# iom480ae register map
Registers are 32-bit, access not given, no defined reset value unless marked. A register's access mark holds for its fields unless they carry their own. Addresses are absolute; registers are grouped by the start of their names; [hi:lo] are bit positions; 'fields as' and 'values as' point back to an identical list.

## TMR01
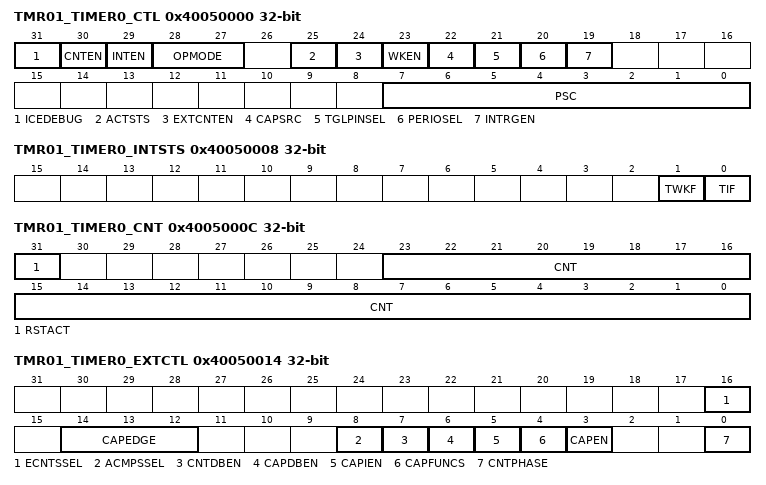
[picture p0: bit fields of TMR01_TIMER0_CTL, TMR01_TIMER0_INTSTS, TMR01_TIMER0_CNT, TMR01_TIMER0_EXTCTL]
0x40050000 TMR01_TIMER0_CTL
  [31] ICEDEBUG, [30] CNTEN, [29] INTEN, [28:27] OPMODE, [25] ACTSTS, [24] EXTCNTEN, [23] WKEN, [22] CAPSRC, [21] TGLPINSEL, [20] PERIOSEL, [19] INTRGEN, [7:0] PSC
0x40050004 TMR01_TIMER0_CMP
  [23:0] CMPDAT
0x40050008 TMR01_TIMER0_INTSTS
  [1] TWKF, [0] TIF
0x4005000C TMR01_TIMER0_CNT
  [31] RSTACT, [23:0] CNT
0x40050010 TMR01_TIMER0_CAP
  [23:0] CAPDAT
0x40050014 TMR01_TIMER0_EXTCTL
  [16] ECNTSSEL, [14:12] CAPEDGE, [8] ACMPSSEL, [7] CNTDBEN, [6] CAPDBEN, [5] CAPIEN, [4] CAPFUNCS, [3] CAPEN, [0] CNTPHASE
0x40050018 TMR01_TIMER0_EINTSTS
  [0] CAPIF
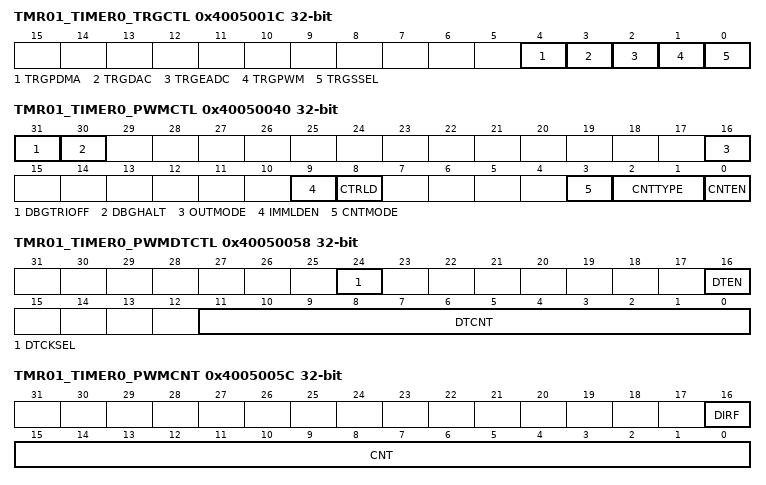
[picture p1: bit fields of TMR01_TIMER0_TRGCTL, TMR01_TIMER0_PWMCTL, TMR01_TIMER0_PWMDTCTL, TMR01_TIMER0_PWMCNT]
0x4005001C TMR01_TIMER0_TRGCTL
  [4] TRGPDMA, [3] TRGDAC, [2] TRGEADC, [1] TRGPWM, [0] TRGSSEL
0x40050020 TMR01_TIMER0_ALTCTL
  [0] FUNCSEL
0x40050040 TMR01_TIMER0_PWMCTL
  [31] DBGTRIOFF, [30] DBGHALT, [16] OUTMODE, [9] IMMLDEN, [8] CTRLD, [3] CNTMODE, [2:1] CNTTYPE, [0] CNTEN
0x40050044 TMR01_TIMER0_PWMCLKSRC
  [2:0] CLKSRC
0x40050048 TMR01_TIMER0_PWMCLKPSC
  [11:0] CLKPSC
0x4005004C TMR01_TIMER0_PWMCNTCLR
  [0] CNTCLR
0x40050050 TMR01_TIMER0_PWMPERIOD
  [15:0] PERIOD
0x40050054 TMR01_TIMER0_PWMCMPDAT
  [15:0] CMP
0x40050058 TMR01_TIMER0_PWMDTCTL
  [24] DTCKSEL, [16] DTEN, [11:0] DTCNT
0x4005005C TMR01_TIMER0_PWMCNT
  [16] DIRF, [15:0] CNT
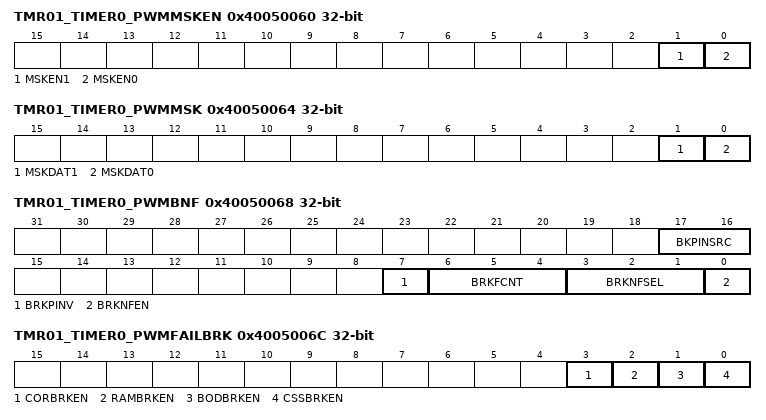
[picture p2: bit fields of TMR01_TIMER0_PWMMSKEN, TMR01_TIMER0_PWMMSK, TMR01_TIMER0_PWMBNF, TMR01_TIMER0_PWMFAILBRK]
0x40050060 TMR01_TIMER0_PWMMSKEN
  [1] MSKEN1, [0] MSKEN0
0x40050064 TMR01_TIMER0_PWMMSK
  [1] MSKDAT1, [0] MSKDAT0
0x40050068 TMR01_TIMER0_PWMBNF
  [17:16] BKPINSRC, [7] BRKPINV, [6:4] BRKFCNT, [3:1] BRKNFSEL, [0] BRKNFEN
0x4005006C TMR01_TIMER0_PWMFAILBRK
  [3] CORBRKEN, [2] RAMBRKEN, [1] BODBRKEN, [0] CSSBRKEN
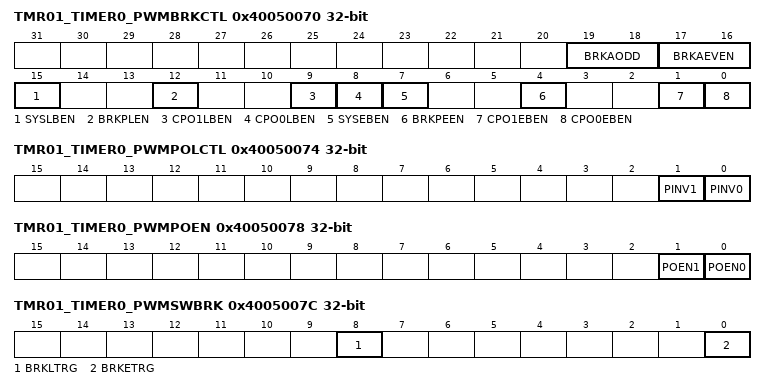
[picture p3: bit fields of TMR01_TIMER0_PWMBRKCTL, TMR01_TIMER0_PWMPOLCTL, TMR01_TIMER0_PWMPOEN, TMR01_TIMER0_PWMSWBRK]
0x40050070 TMR01_TIMER0_PWMBRKCTL
  [19:18] BRKAODD, [17:16] BRKAEVEN, [15] SYSLBEN, [12] BRKPLEN, [9] CPO1LBEN, [8] CPO0LBEN, [7] SYSEBEN, [4] BRKPEEN, [1] CPO1EBEN, [0] CPO0EBEN
0x40050074 TMR01_TIMER0_PWMPOLCTL
  [1] PINV1, [0] PINV0
0x40050078 TMR01_TIMER0_PWMPOEN
  [1] POEN1, [0] POEN0
0x4005007C TMR01_TIMER0_PWMSWBRK
  [8] BRKLTRG, [0] BRKETRG
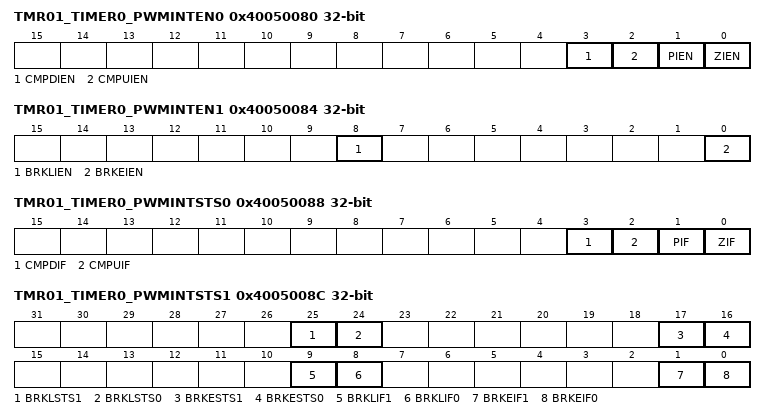
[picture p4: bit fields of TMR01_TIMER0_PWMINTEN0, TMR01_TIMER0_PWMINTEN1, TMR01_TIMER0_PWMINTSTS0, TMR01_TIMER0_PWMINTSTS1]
0x40050080 TMR01_TIMER0_PWMINTEN0
  [3] CMPDIEN, [2] CMPUIEN, [1] PIEN, [0] ZIEN
0x40050084 TMR01_TIMER0_PWMINTEN1
  [8] BRKLIEN, [0] BRKEIEN
0x40050088 TMR01_TIMER0_PWMINTSTS0
  [3] CMPDIF, [2] CMPUIF, [1] PIF, [0] ZIF
0x4005008C TMR01_TIMER0_PWMINTSTS1
  [25] BRKLSTS1, [24] BRKLSTS0, [17] BRKESTS1, [16] BRKESTS0, [9] BRKLIF1, [8] BRKLIF0, [1] BRKEIF1, [0] BRKEIF0
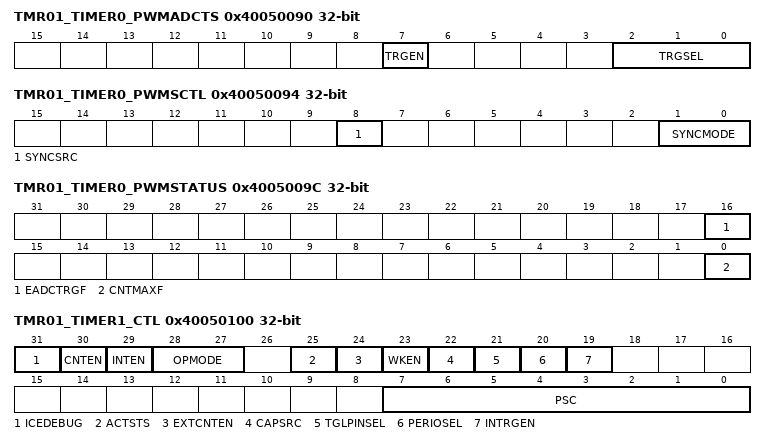
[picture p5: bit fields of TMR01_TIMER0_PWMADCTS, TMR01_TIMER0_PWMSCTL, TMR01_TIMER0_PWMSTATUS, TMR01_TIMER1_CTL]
0x40050090 TMR01_TIMER0_PWMADCTS
  [7] TRGEN, [2:0] TRGSEL
0x40050094 TMR01_TIMER0_PWMSCTL
  [8] SYNCSRC, [1:0] SYNCMODE
0x40050098 TMR01_TIMER0_PWMSTRG
  [0] STRGEN
0x4005009C TMR01_TIMER0_PWMSTATUS
  [16] EADCTRGF, [0] CNTMAXF
0x400500A0 TMR01_TIMER0_PWMPBUF
  [15:0] PBUF
0x400500A4 TMR01_TIMER0_PWMCMPBUF
  [15:0] CMPBUF
0x40050100 TMR01_TIMER1_CTL
  fields as TMR01_TIMER0_CTL
0x40050104 TMR01_TIMER1_CMP
  [23:0] CMPDAT
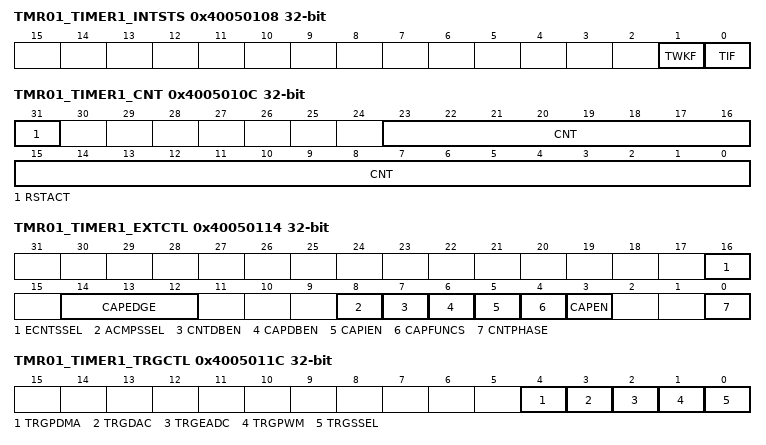
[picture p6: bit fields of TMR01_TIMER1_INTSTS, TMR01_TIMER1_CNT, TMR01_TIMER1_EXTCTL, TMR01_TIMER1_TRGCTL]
0x40050108 TMR01_TIMER1_INTSTS
  [1] TWKF, [0] TIF
0x4005010C TMR01_TIMER1_CNT
  [31] RSTACT, [23:0] CNT
0x40050110 TMR01_TIMER1_CAP
  [23:0] CAPDAT
0x40050114 TMR01_TIMER1_EXTCTL
  fields as TMR01_TIMER0_EXTCTL
0x40050118 TMR01_TIMER1_EINTSTS
  [0] CAPIF
0x4005011C TMR01_TIMER1_TRGCTL
  [4] TRGPDMA, [3] TRGDAC, [2] TRGEADC, [1] TRGPWM, [0] TRGSSEL
0x40050120 TMR01_TIMER1_ALTCTL
  [0] FUNCSEL
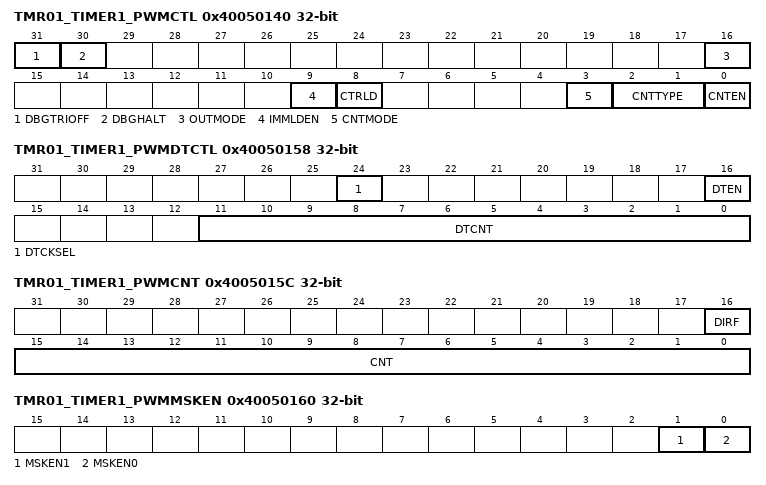
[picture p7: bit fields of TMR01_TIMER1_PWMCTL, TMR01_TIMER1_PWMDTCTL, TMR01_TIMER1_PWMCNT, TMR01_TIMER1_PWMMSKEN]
0x40050140 TMR01_TIMER1_PWMCTL
  fields as TMR01_TIMER0_PWMCTL
0x40050144 TMR01_TIMER1_PWMCLKSRC
  [2:0] CLKSRC
0x40050148 TMR01_TIMER1_PWMCLKPSC
  [11:0] CLKPSC
0x4005014C TMR01_TIMER1_PWMCNTCLR
  [0] CNTCLR
0x40050150 TMR01_TIMER1_PWMPERIOD
  [15:0] PERIOD
0x40050154 TMR01_TIMER1_PWMCMPDAT
  [15:0] CMP
0x40050158 TMR01_TIMER1_PWMDTCTL
  [24] DTCKSEL, [16] DTEN, [11:0] DTCNT
0x4005015C TMR01_TIMER1_PWMCNT
  [16] DIRF, [15:0] CNT
0x40050160 TMR01_TIMER1_PWMMSKEN
  [1] MSKEN1, [0] MSKEN0
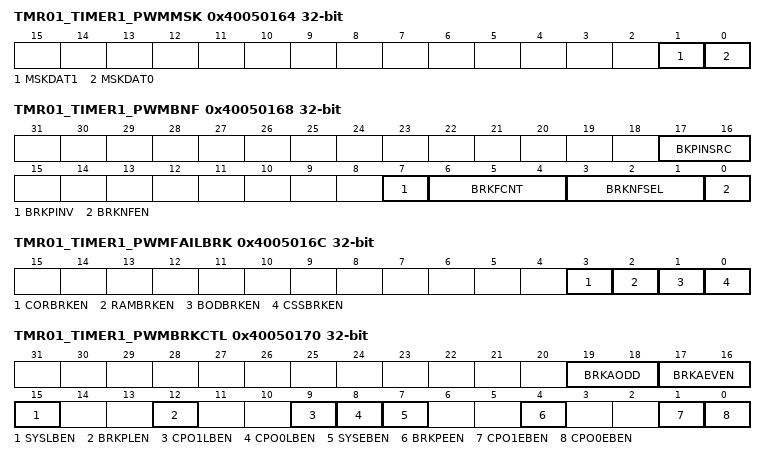
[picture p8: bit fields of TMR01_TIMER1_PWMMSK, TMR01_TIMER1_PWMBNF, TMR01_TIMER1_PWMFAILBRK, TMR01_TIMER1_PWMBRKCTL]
0x40050164 TMR01_TIMER1_PWMMSK
  [1] MSKDAT1, [0] MSKDAT0
0x40050168 TMR01_TIMER1_PWMBNF
  fields as TMR01_TIMER0_PWMBNF
0x4005016C TMR01_TIMER1_PWMFAILBRK
  [3] CORBRKEN, [2] RAMBRKEN, [1] BODBRKEN, [0] CSSBRKEN
0x40050170 TMR01_TIMER1_PWMBRKCTL
  fields as TMR01_TIMER0_PWMBRKCTL
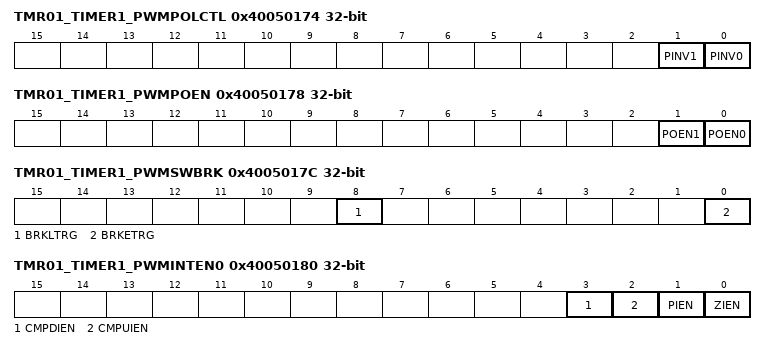
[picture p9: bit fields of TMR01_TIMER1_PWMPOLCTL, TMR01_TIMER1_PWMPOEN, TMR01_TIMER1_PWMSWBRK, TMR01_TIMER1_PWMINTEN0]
0x40050174 TMR01_TIMER1_PWMPOLCTL
  [1] PINV1, [0] PINV0
0x40050178 TMR01_TIMER1_PWMPOEN
  [1] POEN1, [0] POEN0
0x4005017C TMR01_TIMER1_PWMSWBRK
  [8] BRKLTRG, [0] BRKETRG
0x40050180 TMR01_TIMER1_PWMINTEN0
  [3] CMPDIEN, [2] CMPUIEN, [1] PIEN, [0] ZIEN
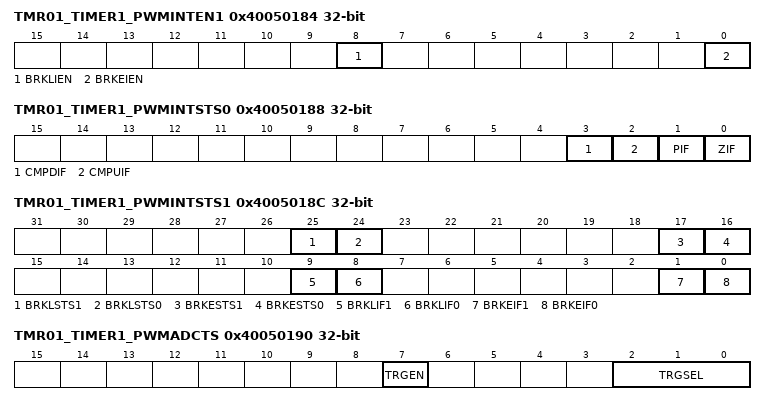
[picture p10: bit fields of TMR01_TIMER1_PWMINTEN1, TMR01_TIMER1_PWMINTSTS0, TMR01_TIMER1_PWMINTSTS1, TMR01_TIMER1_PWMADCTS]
0x40050184 TMR01_TIMER1_PWMINTEN1
  [8] BRKLIEN, [0] BRKEIEN
0x40050188 TMR01_TIMER1_PWMINTSTS0
  [3] CMPDIF, [2] CMPUIF, [1] PIF, [0] ZIF
0x4005018C TMR01_TIMER1_PWMINTSTS1
  fields as TMR01_TIMER0_PWMINTSTS1
0x40050190 TMR01_TIMER1_PWMADCTS
  [7] TRGEN, [2:0] TRGSEL
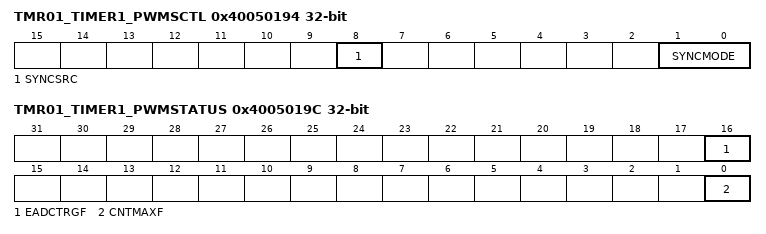
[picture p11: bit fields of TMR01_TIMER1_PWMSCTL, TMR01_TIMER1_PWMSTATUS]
0x40050194 TMR01_TIMER1_PWMSCTL
  [8] SYNCSRC, [1:0] SYNCMODE
0x4005019C TMR01_TIMER1_PWMSTATUS
  [16] EADCTRGF, [0] CNTMAXF
0x400501A0 TMR01_TIMER1_PWMPBUF
  [15:0] PBUF
0x400501A4 TMR01_TIMER1_PWMCMPBUF
  [15:0] CMPBUF
